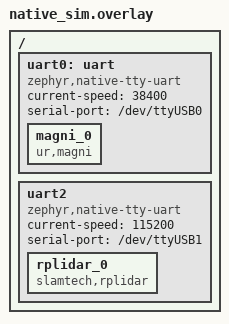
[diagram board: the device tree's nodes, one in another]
/* Copyright (c) 2026 Tilmann Unte
 * SPDX-License-Identifier:  Apache-2.0
 */

/ {
	uart0: uart {
		status = "okay";
		compatible = "zephyr,native-tty-uart";
		current-speed = <38400>;
		serial-port = "/dev/ttyUSB0";
		
		magni_0 {
			compatible = "ur,magni";
		};
	};

	uart2: uart2 {
		status = "okay";
		compatible = "zephyr,native-tty-uart";
		current-speed = <115200>;
		serial-port = "/dev/ttyUSB1";
		
		rplidar_0 {
			compatible = "slamtech,rplidar";
			status = "okay";
		};
	};
};
